# R7FA6M3AH register map
Vendor: Renesas; Series: RA6; File version: 1.2
CPU: CM4 r0p1, little endian, MPU, FPU, VTOR, 4 interrupt priority bits
Registers are 32-bit, read-write, reset 0x0 unless marked. A register's access mark holds for its fields unless they carry their own. Offsets are from the block's base; [hi:lo] are bit positions; {n}, {i} and the like mark numbered series; 'fields as' and 'values as' point back to an identical list.

## PFS — Pmn Pin Function Control Register
Base 0x40040800
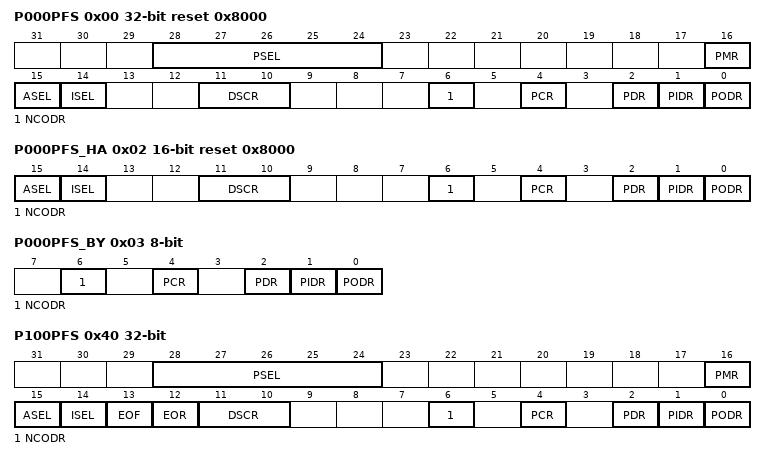
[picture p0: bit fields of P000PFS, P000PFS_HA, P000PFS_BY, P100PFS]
0x00 P000PFS reset 0x8000 (reset mask 0xFFFFFFFD) — P000 Pin Function Control Register
  [28:24] PSEL — Port Function SelectThese bits select the peripheral function. For individual pin functions, see the MPC table
  [16] PMR — Port Mode Control
  [15] ASEL — Analog Input enable
  [14] ISEL — IRQ input enable
  [11:10] DSCR — Drive Strength Control Register
  [6] NCODR — N,Channel Open Drain Control
  [4] PCR — Pull,up Control
  [2] PDR — Port Direction
  [1] PIDR ro — Port Input Data
  [0] PODR — Port Output Data
0x02 P000PFS_HA 16-bit reset 0x8000 (reset mask 0xFFFD) (alternate view of P000PFS) — P000 Pin Function Control Register
  [15] ASEL — Analog Input enable
  [14] ISEL — IRQ input enable
  [11:10] DSCR — Drive Strength Control Register
  [6] NCODR — N,Channel Open Drain Control
  [4] PCR — Pull,up Control
  [2] PDR — Port Direction
  [1] PIDR ro — Port Input Data
  [0] PODR — Port Output Data
0x03 P000PFS_BY 8-bit (reset mask 0xFD) (alternate view of P000PFS) — P000 Pin Function Control Register
  [6] NCODR — N,Channel Open Drain Control
  [4] PCR — Pull,up Control
  [2] PDR — Port Direction
  [1] PIDR ro — Port Input Data
  [0] PODR — Port Output Data
{0x0+4i} P00{i}PFS (i=1..7) reset 0x8000 (reset mask 0xFFFFFFFD) — P00{i} Pin Function Control Register
{0x2+4i} P00{i}PFS_HA (i=1..7) 16-bit reset 0x8000 (reset mask 0xFFFD) (alternate view of P00{i}PFS) — P00{i} Pin Function Control Register
{0x3+4i} P00{i}PFS_BY (i=1..7) 8-bit (reset mask 0xFD) (alternate view of P00{i}PFS) — P00{i} Pin Function Control Register
{0x0+4i} P00{i}PFS_1 (i=8..9) (reset mask 0xFFFFFFFD) — P00{i} Pin Function Control Register
{0x2+4i} P00{i}PFS_HA_1 (i=8..9) 16-bit (reset mask 0xFFFD) (alternate view of P00{i}PFS) — P00{i} Pin Function Control Register
{0x3+4i} P00{i}PFS_BY_1 (i=8..9) 8-bit (reset mask 0xFD) (alternate view of P00{i}PFS) — P00{i} Pin Function Control Register
0x28 P010PFS (reset mask 0xFFFFFFFD) — P010 Pin Function Control Register
0x30 P010PFS_HA 16-bit (reset mask 0xFFFD) — P010 Pin Function Control Register
0x31 P010PFS_BY 8-bit (reset mask 0xFD) — P010 Pin Function Control Register
{0x0+4i} P0{i}PFS (i=14..15) (reset mask 0xFFFFFFFD) — P0{i} Pin Function Control Register
{0x2+4i} P0{i}PFS_HA (i=14..15) 16-bit (reset mask 0xFFFD) — P0{i} Pin Function Control Register
{0x3+4i} P0{i}PFS_BY (i=14..15) 8-bit (reset mask 0xFD) — P0{i} Pin Function Control Register
0x40 P100PFS (reset mask 0xFFFFFFFD) — P100 Pin Function Control Register
  [28:24] PSEL — Port Function SelectThese bits select the peripheral function. For individual pin functions, see the MPC table
  [16] PMR — Port Mode Control
  [15] ASEL — Analog Input enable
  [14] ISEL — IRQ input enable
  [13] EOF — Event on Falling
  [12] EOR — Event on Rising
  [11:10] DSCR — Drive Strength Control Register
  [6] NCODR — N,Channel Open Drain Control
  [4] PCR — Pull,up Control
  [2] PDR — Port Direction
  [1] PIDR ro — Port Input Data
  [0] PODR — Port Output Data
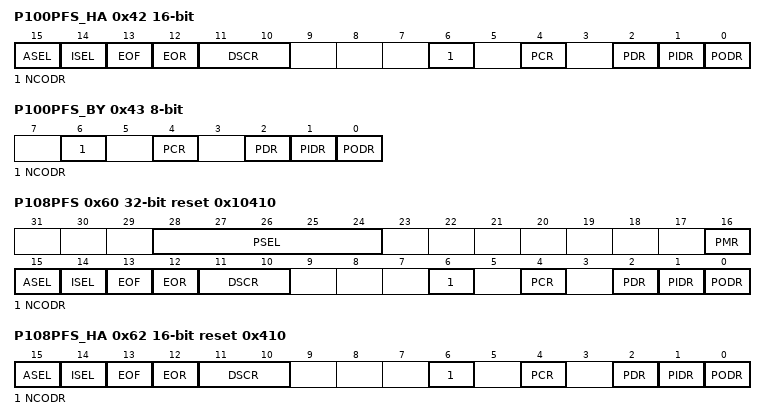
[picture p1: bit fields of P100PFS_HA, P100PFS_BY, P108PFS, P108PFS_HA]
0x42 P100PFS_HA 16-bit (reset mask 0xFFFD) — P100 Pin Function Control Register
  [15] ASEL — Analog Input enable
  [14] ISEL — IRQ input enable
  [13] EOF — Event on Falling
  [12] EOR — Event on Rising
  [11:10] DSCR — Drive Strength Control Register
  [6] NCODR — N,Channel Open Drain Control
  [4] PCR — Pull,up Control
  [2] PDR — Port Direction
  [1] PIDR ro — Port Input Data
  [0] PODR — Port Output Data
0x43 P100PFS_BY 8-bit (reset mask 0xFD) — P100 Pin Function Control Register
  fields as P000PFS_BY
{0x40+4i} P10{i}PFS (i=1..7) (reset mask 0xFFFFFFFD) (alternate view of P10{i}PFS) — P10{i} Pin Function Control Register
{0x42+4i} P10{i}PFS_HA (i=1..7) 16-bit (reset mask 0xFFFD) (alternate view of P10{i}PFS) — P10{i} Pin Function Control Register
{0x43+4i} P10{i}PFS_BY (i=1..7) 8-bit (reset mask 0xFD) (alternate view of P10{i}PFS) — P10{i} Pin Function Control Register
0x60 P108PFS reset 0x10410 (reset mask 0xFFFFFFFD) — P108 Pin Function Control Register
  fields as P100PFS
0x62 P108PFS_HA 16-bit reset 0x410 (reset mask 0xFFFD) (alternate view of P108PFS) — P108 Pin Function Control Register
  fields as P100PFS_HA
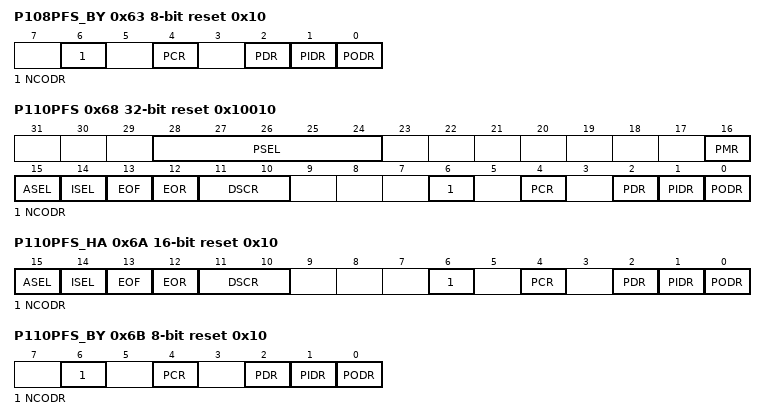
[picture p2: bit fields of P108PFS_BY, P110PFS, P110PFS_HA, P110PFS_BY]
0x63 P108PFS_BY 8-bit reset 0x10 (reset mask 0xFD) (alternate view of P108PFS) — P108 Pin Function Control Register
  fields as P000PFS_BY
0x64 P109PFS reset 0x10410 (reset mask 0xFFFFFFFD) — P109 Pin Function Control Register
0x66 P109PFS_HA 16-bit reset 0x410 (reset mask 0xFFFD) (alternate view of P109PFS) — P109 Pin Function Control Register
0x67 P109PFS_BY 8-bit reset 0x10 (reset mask 0xFD) (alternate view of P109PFS) — P109 Pin Function Control Register
0x68 P110PFS reset 0x10010 (reset mask 0xFFFFFFFD) — P110 Pin Function Control Register
  fields as P100PFS
0x6A P110PFS_HA 16-bit reset 0x10 (reset mask 0xFFFD) (alternate view of P110PFS) — P110 Pin Function Control Register
  fields as P100PFS_HA
0x6B P110PFS_BY 8-bit reset 0x10 (reset mask 0xFD) (alternate view of P110PFS) — P110 Pin Function Control Register
  fields as P000PFS_BY
{0x40+4i} P1{i}PFS (i=11..15) (reset mask 0xFFFFFFFD) — P1{i} Pin Function Control Register
{0x42+4i} P1{i}PFS_HA (i=11..15) 16-bit (reset mask 0xFFFD) (alternate view of P1{i}PFS) — P1{i} Pin Function Control Register
{0x43+4i} P1{i}PFS_BY (i=11..15) 8-bit (reset mask 0xFD) (alternate view of P1{i}PFS) — P1{i} Pin Function Control Register
0x80 P200PFS (reset mask 0xFFFFFFFD) — P200 Pin Function Control Register
0x82 P200PFS_HA 16-bit (reset mask 0xFFFD) (alternate view of P200PFS) — P200 Pin Function Control Register
0x83 P200PFS_BY 8-bit (reset mask 0xFD) (alternate view of P200PFS) — P200 Pin Function Control Register
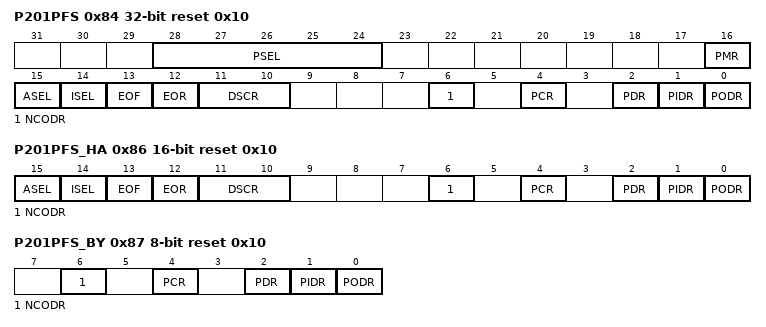
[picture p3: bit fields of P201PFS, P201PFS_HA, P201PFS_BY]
0x84 P201PFS reset 0x10 (reset mask 0xFFFFFFFD) — P201 Pin Function Control Register
  fields as P100PFS
0x86 P201PFS_HA 16-bit reset 0x10 (reset mask 0xFFFD) (alternate view of P201PFS) — P201 Pin Function Control Register
  fields as P100PFS_HA
0x87 P201PFS_BY 8-bit reset 0x10 (reset mask 0xFD) (alternate view of P201PFS) — P201 Pin Function Control Register
  fields as P000PFS_BY
{0x80+4i} P20{i}PFS (i=2..9) (reset mask 0xFFFFFFFD) — P20{i} Pin Function Control Register
{0x82+4i} P20{i}PFS_HA (i=2..9) 16-bit (reset mask 0xFFFD) (alternate view of P20{i}PFS) — P20{i} Pin Function Control Register
{0x83+4i} P20{i}PFS_BY (i=2..9) 8-bit (reset mask 0xFD) (alternate view of P20{i}PFS) — P20{i} Pin Function Control Register
{0x80+4i} P2{i}PFS (i=10..14) (reset mask 0xFFFFFFFD) — P2{i} Pin Function Control Register
{0x82+4i} P2{i}PFS_HA (i=10..14) 16-bit (reset mask 0xFFFD) (alternate view of P2{i}PFS) — P2{i} Pin Function Control Register
{0x83+4i} P2{i}PFS_BY (i=10..14) 8-bit (reset mask 0xFD) (alternate view of P2{i}PFS) — P2{i} Pin Function Control Register
0xC0 P300PFS reset 0x10010 (reset mask 0xFFFFFFFD) — P300 Pin Function Control Register
0xC2 P300PFS_HA 16-bit reset 0x10 (reset mask 0xFFFD) (alternate view of P300PFS) — P300 Pin Function Control Register
0xC3 P300PFS_BY 8-bit reset 0x10 (reset mask 0xFD) (alternate view of P300PFS) — P300 Pin Function Control Register
{0xC0+4i} P30{i}PFS (i=1..9) (reset mask 0xFFFFFFFD) — P30{i} Pin Function Control Register
{0xC2+4i} P30{i}PFS_HA (i=1..9) 16-bit (reset mask 0xFFFD) (alternate view of P30{i}PFS) — P30{i} Pin Function Control Register
{0xC3+4i} P30{i}PFS_BY (i=1..9) 8-bit (reset mask 0xFD) (alternate view of P30{i}PFS) — P30{i} Pin Function Control Register
{0xC0+4i} P3{i}PFS (i=10..15) (reset mask 0xFFFFFFFD) — P3{i} Pin Function Control Register
{0xC2+4i} P3{i}PFS_HA (i=10..15) 16-bit (reset mask 0xFFFD) (alternate view of P3{i}PFS) — P30{i} Pin Function Control Register
{0xC3+4i} P3{i}PFS_BY (i=10..15) 8-bit (reset mask 0xFD) (alternate view of P3{i}PFS) — P30{i} Pin Function Control Register
{0x100+4i} P40{i}PFS (i=0..9) (reset mask 0xFFFFFFFD) — P40{i} Pin Function Control Register
{0x102+4i} P40{i}PFS_HA (i=0..9) 16-bit (reset mask 0xFFFD) (alternate view of P40{i}PFS) — P40{i} Pin Function Control Register
{0x103+4i} P40{i}PFS_BY (i=0..9) 8-bit (reset mask 0xFD) (alternate view of P40{i}PFS) — P40{i} Pin Function Control Register
{0x100+4i} P4{i}PFS (i=10..15) (reset mask 0xFFFFFFFD) — P4{i} Pin Function Control Register
{0x102+4i} P4{i}PFS_HA (i=10..15) 16-bit (reset mask 0xFFFD) (alternate view of P4{i}PFS) — P4{i} Pin Function Control Register
{0x103+4i} P4{i}PFS_BY (i=10..15) 8-bit (reset mask 0xFD) (alternate view of P4{i}PFS) — P4{i} Pin Function Control Register
{0x140+4i} P50{i}PFS (i=0..8) (reset mask 0xFFFFFFFD) — P50{i} Pin Function Control Register
{0x142+4i} P50{i}PFS_HA (i=0..8) 16-bit (reset mask 0xFFFD) (alternate view of P50{i}PFS) — P50{i} Pin Function Control Register
{0x143+4i} P50{i}PFS_BY (i=0..8) 8-bit (reset mask 0xFD) (alternate view of P50{i}PFS) — P50{i} Pin Function Control Register
{0x140+4i} P5{i}PFS (i=11..15) (reset mask 0xFFFFFFFD) — P5{i} Pin Function Control Register
{0x142+4i} P5{i}PFS_HA (i=11..15) 16-bit (reset mask 0xFFFD) (alternate view of P5{i}PFS) — P5{i} Pin Function Control Register
{0x143+4i} P5{i}PFS_BY (i=11..15) 8-bit (reset mask 0xFD) (alternate view of P5{i}PFS) — P5{i} Pin Function Control Register
{0x180+4i} P60{i}PFS (i=0..9) (reset mask 0xFFFFFFFD) — P60{i} Pin Function Control Register
{0x182+4i} P60{i}PFS_HA (i=0..9) 16-bit (reset mask 0xFFFD) (alternate view of P60{i}PFS) — P60{i} Pin Function Control Register
{0x183+4i} P60{i}PFS_BY (i=0..9) 8-bit (reset mask 0xFD) (alternate view of P60{i}PFS) — P60{i} Pin Function Control Register
{0x180+4i} P6{i}PFS (i=10..15) (reset mask 0xFFFFFFFD) — P6{i} Pin Function Control Register
{0x182+4i} P6{i}PFS_HA (i=10..15) 16-bit (reset mask 0xFFFD) (alternate view of P6{i}PFS) — P6{i} Pin Function Control Register
{0x183+4i} P6{i}PFS_BY (i=10..15) 8-bit (reset mask 0xFD) (alternate view of P6{i}PFS) — P6{i} Pin Function Control Register
{0x1C0+4i} P70{i}PFS (i=0..8) (reset mask 0xFFFFFFFD) — P70{i} Pin Function Control Register
{0x1C2+4i} P70{i}PFS_HA (i=0..8) 16-bit (reset mask 0xFFFD) (alternate view of P70{i}PFS) — P70{i} Pin Function Control Register
{0x1C3+4i} P70{i}PFS_BY (i=0..8) 8-bit (reset mask 0xFD) (alternate view of P70{i}PFS) — P70{i} Pin Function Control Register
{0x200+4i} P80{i}PFS (i=0..6) (reset mask 0xFFFFFFFD) — P80{i} Pin Function Control Register
{0x202+4i} P80{i}PFS_HA (i=0..6) 16-bit (reset mask 0xFFFD) (alternate view of P80{i}PFS) — P80{i} Pin Function Control Register
{0x203+4i} P80{i}PFS_BY (i=0..6) 8-bit (reset mask 0xFD) (alternate view of P80{i}PFS) — P80{i} Pin Function Control Register
{0x240+4i} P90{i}PFS (i=0..1) (reset mask 0xFFFFFFFD) — P90{i} Pin Function Control Register
{0x242+4i} P90{i}PFS_HA (i=0..1) 16-bit (reset mask 0xFFFD) (alternate view of P90{i}PFS) — P90{i} Pin Function Control Register
{0x243+4i} P90{i}PFS_BY (i=0..1) 8-bit (reset mask 0xFD) (alternate view of P90{i}PFS) — P90{i} Pin Function Control Register
{0x240+4i} P90{i}PFS_1 (i=5..8) (reset mask 0xFFFFFFFD) — P90{i} Pin Function Control Register
{0x242+4i} P90{i}PFS_HA_1 (i=5..8) 16-bit (reset mask 0xFFFD) (alternate view of P90{i}PFS) — P90{i} Pin Function Control Register
{0x243+4i} P90{i}PFS_BY_1 (i=5..8) 8-bit (reset mask 0xFD) (alternate view of P90{i}PFS) — P90{i} Pin Function Control Register
{0x280+4i} PA0{i}PFS (i=0..1) (reset mask 0xFFFFFFFD) — PA0{i} Pin Function Control Register
{0x282+4i} PA0{i}PFS_HA (i=0..1) 16-bit (reset mask 0xFFFD) (alternate view of PA0{i}PFS) — PA0{i} Pin Function Control Register
{0x283+4i} PA0{i}PFS_BY (i=0..1) 8-bit (reset mask 0xFD) (alternate view of PA0{i}PFS) — PA0{i} Pin Function Control Register
{0x280+4i} PA0{i}PFS_1 (i=8..9) (reset mask 0xFFFFFFFD) — PA0{i} Pin Function Control Register
{0x282+4i} PA0{i}PFS_HA_1 (i=8..9) 16-bit (reset mask 0xFFFD) (alternate view of PA0{i}PFS) — PA0{i} Pin Function Control Register
{0x283+4i} PA0{i}PFS_BY_1 (i=8..9) 8-bit (reset mask 0xFD) (alternate view of PA0{i}PFS) — PA0{i} Pin Function Control Register
0x2A8 PA10PFS (reset mask 0xFFFFFFFD) — PA10 Pin Function Control Register
0x2AA PA10PFS_HA 16-bit (reset mask 0xFFFD) (alternate view of PA10PFS) — PA10 Pin Function Control Register
0x2AB PA10PFS_BY 8-bit (reset mask 0xFD) (alternate view of PA10PFS) — PA10 Pin Function Control Register
{0x2C0+4i} PB0{i}PFS (i=0..1) (reset mask 0xFFFFFFFD) — PB0{i} Pin Function Control Register
{0x2C2+4i} PB0{i}PFS_HA (i=0..1) 16-bit (reset mask 0xFFFD) (alternate view of PB0{i}PFS) — PB0{i} Pin Function Control Register
{0x2C3+4i} PB0{i}PFS_BY (i=0..1) 8-bit (reset mask 0xFD) (alternate view of PB0{i}PFS) — PB0{i} Pin Function Control Register
